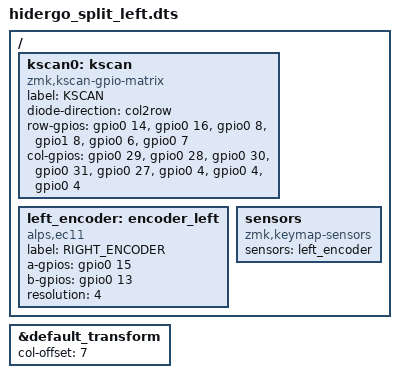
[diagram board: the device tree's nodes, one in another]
#include "hidergo_split.dts"

&default_transform {// The matrix transform for this board is 6 columns over because the left half is 6 columns wide according to the matrix.
    col-offset = <7>;
};


/{

    kscan0: kscan {
        compatible = "zmk,kscan-gpio-matrix";
        label = "KSCAN";
        diode-direction = "col2row";

        row-gpios
        = <&gpio0 14 (GPIO_ACTIVE_HIGH | GPIO_PULL_DOWN)> // Row 0 from the schematic file
        , <&gpio0 16 (GPIO_ACTIVE_HIGH | GPIO_PULL_DOWN)> // Row 1 from the schematic file
        , <&gpio0 8 (GPIO_ACTIVE_HIGH | GPIO_PULL_DOWN)> // Row 2 from the schematic file
        , <&gpio1 8 (GPIO_ACTIVE_HIGH | GPIO_PULL_DOWN)> // Row 2 from the schematic file
        , <&gpio0 6 (GPIO_ACTIVE_HIGH | GPIO_PULL_DOWN)> // Row 3 from the schematic file
        , <&gpio0 7 (GPIO_ACTIVE_HIGH | GPIO_PULL_DOWN)> // Row 4 from the schematic file


        ;
        //TODO: need to add col 6 and 7
        col-gpios
        = <&gpio0 29 GPIO_ACTIVE_HIGH> // Col 1 in the schematic
        , <&gpio0 28 GPIO_ACTIVE_HIGH> // Col 2 in the schematic
        , <&gpio0 30 GPIO_ACTIVE_HIGH> // Col 2 in the schematic
        , <&gpio0 31 GPIO_ACTIVE_HIGH> // Col 3 in the schematic
        , <&gpio0 27 GPIO_ACTIVE_HIGH> // Col 4 in the schematic
        , <&gpio0 4 GPIO_ACTIVE_HIGH> // Col 5 in the schematic
        , <&gpio0 4 GPIO_ACTIVE_HIGH> // Col 5 in the schematic
        , <&gpio0 4 GPIO_ACTIVE_HIGH> // Col 5 in the schematic
        ;
    };
    left_encoder: encoder_left {
        compatible = "alps,ec11";
        label = "RIGHT_ENCODER";
        a-gpios = <&gpio0 15 (GPIO_ACTIVE_HIGH | GPIO_PULL_UP)>;
        b-gpios = <&gpio0 13 (GPIO_ACTIVE_HIGH | GPIO_PULL_UP)>;
        resolution = <4>;
    };

    sensors {
        compatible = "zmk,keymap-sensors";
        sensors = <&left_encoder>;
    };
};


&left_encoder {
    status = "okay";
};

